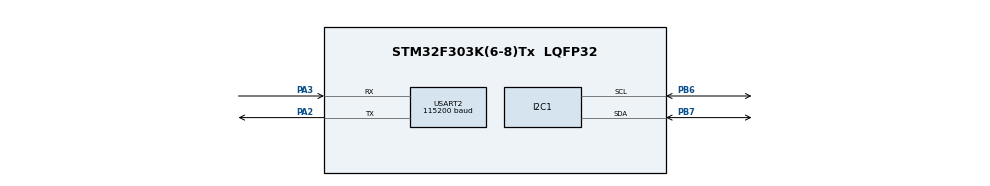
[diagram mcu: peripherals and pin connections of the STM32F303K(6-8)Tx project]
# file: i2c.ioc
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I2C1.OwnAddress=1
Mcu.Family=STM32F3
Mcu.Name=STM32F303K(6-8)Tx
Mcu.Package=LQFP32
NVIC.I2C1_EV_IRQn=true\:0\:0\:false\:false\:true\:true\:true\:true
NVIC.PriorityGroup=NVIC_PRIORITYGROUP_4
NVIC.USART2_IRQn=true\:0\:0\:false\:false\:true\:true\:true\:true
PA13.Mode=Trace_Asynchronous_SW
PA13.Signal=SYS_JTMS-SWDIO
PA14.Mode=Trace_Asynchronous_SW
PA14.Signal=SYS_JTCK-SWCLK
PA2.Mode=Asynchronous
PA2.Signal=USART2_TX
PA3.Mode=Asynchronous
PA3.Signal=USART2_RX
PB3.Mode=Trace_Asynchronous_SW
PB3.Signal=SYS_JTDO-TRACESWO
PB6.Mode=I2C
PB6.Signal=I2C1_SCL
PB7.Mode=I2C
PB7.Signal=I2C1_SDA
ProjectManager.HeapSize=0x200
ProjectManager.StackSize=0x400
ProjectManager.TargetToolchain=STM32CubeIDE
RCC.AHBFreq_Value=8000000
RCC.APB1Freq_Value=8000000
RCC.APB2Freq_Value=8000000
RCC.CortexFreq_Value=8000000
RCC.HSE_VALUE=8000000
RCC.HSI_VALUE=8000000
RCC.SYSCLKFreq_VALUE=8000000
USART2.BaudRate=115200
USART2.VirtualMode-Asynchronous=VM_ASYNC
board=custom

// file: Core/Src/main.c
/* USER CODE BEGIN Header */
/**
  ******************************************************************************
  * @file           : main.c
  * @brief          : Main program body
  ******************************************************************************
  * @attention
  *
  * Copyright (c) 2023 STMicroelectronics.
  * All rights reserved.
  *
  * This software is licensed under terms that can be found in the LICENSE file
  * in the root directory of this software component.
  * If no LICENSE file comes with this software, it is provided AS-IS.
  *
  ******************************************************************************
  */
/* USER CODE END Header */
#include "main.h"
#include "i2c.h"
#include "usart.h"
#include "gpio.h"
#include "HTS221.h"
#include "LPS25HB.h"
#include "string.h"
#include "stdio.h"

/* USER CODE BEGIN PD */
// I2C slave device useful information
#define 	LSM6DS0_DEVICE_ADDRESS		0xD6U
#define 	LSM6DS0_WHO_AM_I_VALUE		0x68U
#define 	LSM6DS0_WHO_AM_I_ADDRES		0x0FU

/* USER CODE END PD */

uint8_t tx_data[128] ;
volatile float temperature = 0;
volatile uint8_t humidity = 0;
volatile float preassure = 0;
float altitude = 0;

void SystemClock_Config(void);

int main(void)
{

  /* MCU Configuration--------------------------------------------------------*/

  /* Reset of all peripherals, Initializes the Flash interface and the Systick. */
  LL_APB2_GRP1_EnableClock(LL_APB2_GRP1_PERIPH_SYSCFG);
  LL_APB1_GRP1_EnableClock(LL_APB1_GRP1_PERIPH_PWR);

  /* System interrupt init*/
  NVIC_SetPriorityGrouping(NVIC_PRIORITYGROUP_4);

  /* SysTick_IRQn interrupt configuration */
  NVIC_SetPriority(SysTick_IRQn, NVIC_EncodePriority(NVIC_GetPriorityGrouping(),15, 0));

  /* Configure the system clock */
  SystemClock_Config();

  /* Initialize all configured peripherals */
  MX_GPIO_Init();
  MX_I2C1_Init();
  MX_USART2_UART_Init();

  /* USER CODE BEGIN 2 */

  HTS221_init();
  LPS25HB_init();
  float initial_preassure = LPS25HB_get_pressure();

  /* USER CODE END 2 */

  /* Infinite loop */
  /* USER CODE BEGIN WHILE */
     while (1)
     {

   	  temperature = HTS221_get_temperature();
   	  humidity = HTS221_get_humidity();
   	  preassure = LPS25HB_get_pressure();
   	  altitude = LPS25HB_get_altitude(initial_preassure,preassure,temperature);

   	  format_string(tx_data,temperature,humidity,preassure,altitude);
   	  uint8_t tx_data_len = (uint8_t) strlen((char*) tx_data);
   	  UART_SEND_DATA(tx_data, tx_data_len);
   	  LL_mDelay(1000);
}

  /* USER CODE END 2 */

  /* Infinite loop */
  /* USER CODE BEGIN WHILE */

  /* USER CODE END 3 */
}

void SystemClock_Config(void)
{
  LL_FLASH_SetLatency(LL_FLASH_LATENCY_0);
  while(LL_FLASH_GetLatency()!= LL_FLASH_LATENCY_0)
  {
  }
  LL_RCC_HSI_Enable();

   /* Wait till HSI is ready */
  while(LL_RCC_HSI_IsReady() != 1)
  {

  }
  LL_RCC_HSI_SetCalibTrimming(16);
  LL_RCC_SetAHBPrescaler(LL_RCC_SYSCLK_DIV_1);
  LL_RCC_SetAPB1Prescaler(LL_RCC_APB1_DIV_1);
  LL_RCC_SetAPB2Prescaler(LL_RCC_APB2_DIV_1);
  LL_RCC_SetSysClkSource(LL_RCC_SYS_CLKSOURCE_HSI);

   /* Wait till System clock is ready */
  while(LL_RCC_GetSysClkSource() != LL_RCC_SYS_CLKSOURCE_STATUS_HSI)
  {

  }
  LL_Init1msTick(8000000);
  LL_SetSystemCoreClock(8000000);
  LL_RCC_SetI2CClockSource(LL_RCC_I2C1_CLKSOURCE_HSI);
}

/* USER CODE BEGIN 4 */
void format_string(uint8_t* final_string,float temperature, uint8_t humidity,float preassure, float relative_height){
	uint8_t data[] = "%.2f,%d,%.2f,%.2f \n \r";
	sprintf((char*)final_string, (char*) data,temperature ,humidity,preassure,relative_height);

}

/* USER CODE END 4 */

void Error_Handler(void)
{
  __disable_irq();
  while (1)
  {
  }
}
